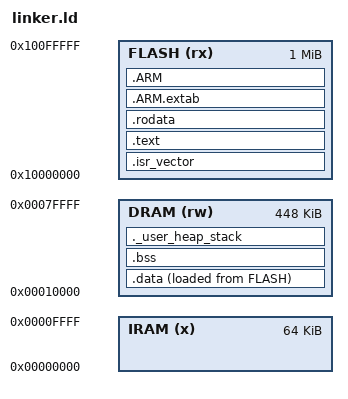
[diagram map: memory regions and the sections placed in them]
/* XR871 Linker Script - ESP32-style memory layout */
MEMORY
{
  /* Internal SRAM */
  IRAM (x) : ORIGIN = 0x00000000, LENGTH = 64K
  DRAM (rw) : ORIGIN = 0x00010000, LENGTH = 448K
  /* External SPI Flash */
  FLASH (rx) : ORIGIN = 0x10000000, LENGTH = 1024K
}

/* Stack */
_estack = ORIGIN(DRAM) + LENGTH(DRAM);

/* Heap */
_Min_Heap_Size = 0x20000;
_Min_Stack_Size = 0x4000;

/* Entry point */
ENTRY(Reset_Handler)

/* Sections */
SECTIONS
{
  /* Vector table */
  .isr_vector :
  {
    . = ALIGN(4);
    KEEP(*(.isr_vector))
    . = ALIGN(4);
  } >FLASH

  /* Program code */
  .text :
  {
    . = ALIGN(4);
    *(.text)
    *(.text*)
    *(.glue_7)
    *(.glue_7t)
    *(.eh_frame)
    KEEP(*(.init))
    KEEP(*(.fini))
    . = ALIGN(4);
    _etext = .;
  } >FLASH

  /* Read-only data */
  .rodata :
  {
    . = ALIGN(4);
    *(.rodata)
    *(.rodata*)
    . = ALIGN(4);
  } >FLASH

  /* ARM exception handling */
  .ARM.extab :
  {
    *(.ARM.extab* .gnu.linkonce.armextab.*)
  } >FLASH
  .ARM :
  {
    __exidx_start = .;
    *(.ARM.exidx*)
    __exidx_end = .;
  } >FLASH

  /* Initialized data */
  .data :
  {
    . = ALIGN(4);
    _sdata = .;
    *(.data)
    *(.data*)
    . = ALIGN(4);
    _edata = .;
  } >DRAM AT> FLASH

  /* Uninitialized data */
  .bss :
  {
    . = ALIGN(4);
    _sbss = .;
    __bss_start__ = _sbss;
    *(.bss)
    *(.bss*)
    *(COMMON)
    . = ALIGN(4);
    _ebss = .;
    __bss_end__ = _ebss;
  } >DRAM

  /* User heap */
  ._user_heap_stack :
  {
    . = ALIGN(8);
    PROVIDE(end = .);
    PROVIDE(_end = .);
    . = . + _Min_Heap_Size;
    . = . + _Min_Stack_Size;
    . = ALIGN(8);
  } >DRAM

  /* Debug info */
  .debug_info 0 : { *(.debug_info) }
  .debug_abbrev 0 : { *(.debug_abbrev) }
  .debug_line 0 : { *(.debug_line) }
  .debug_frame 0 : { *(.debug_frame) }
  .debug_str 0 : { *(.debug_str) }
  .debug_loc 0 : { *(.debug_loc) }
  .debug_ranges 0 : { *(.debug_ranges) }
}
